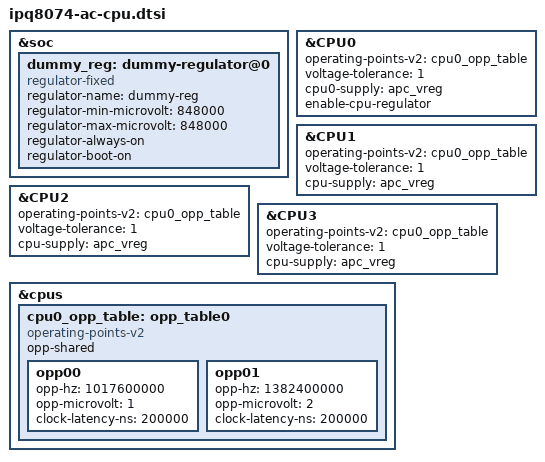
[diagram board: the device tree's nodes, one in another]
/*
 * Copyright (c) 2016-2018,2020 The Linux Foundation. All rights reserved.
 *
 * Permission to use, copy, modify, and/or distribute this software for any
 * purpose with or without fee is hereby granted, provided that the above
 * copyright notice and this permission notice appear in all copies.
 *
 * THE SOFTWARE IS PROVIDED "AS IS" AND THE AUTHOR DISCLAIMS ALL WARRANTIES
 * WITH REGARD TO THIS SOFTWARE INCLUDING ALL IMPLIED WARRANTIES OF
 * MERCHANTABILITY AND FITNESS. IN NO EVENT SHALL THE AUTHOR BE LIABLE FOR
 * ANY SPECIAL, DIRECT, INDIRECT, OR CONSEQUENTIAL DAMAGES OR ANY DAMAGES
 * WHATSOEVER RESULTING FROM LOSS OF USE, DATA OR PROFITS, WHETHER IN AN
 * ACTION OF CONTRACT, NEGLIGENCE OR OTHER TORTIOUS ACTION, ARISING OUT OF
 * OR IN CONNECTION WITH THE USE OR PERFORMANCE OF THIS SOFTWARE.
 */

&soc {
	dummy_reg: dummy-regulator@0 {
		compatible = "regulator-fixed";
		regulator-name = "dummy-reg";
		regulator-min-microvolt = <848000>;
		regulator-max-microvolt = <848000>;
		regulator-always-on;
		regulator-boot-on;
	};
};

&CPU0 {
	operating-points-v2 = <&cpu0_opp_table>;
	voltage-tolerance = <1>;
	cpu0-supply = <&apc_vreg>;
	enable-cpu-regulator;
};

&CPU1 {
	operating-points-v2 = <&cpu0_opp_table>;
	voltage-tolerance = <1>;
	cpu-supply = <&apc_vreg>;
};

&CPU2 {
	operating-points-v2 = <&cpu0_opp_table>;
	voltage-tolerance = <1>;
	cpu-supply = <&apc_vreg>;
};

&CPU3 {
	operating-points-v2 = <&cpu0_opp_table>;
	voltage-tolerance = <1>;
	cpu-supply = <&apc_vreg>;
};

&cpus {
	cpu0_opp_table: opp_table0 {
		compatible = "operating-points-v2";
		opp-shared;

		opp00 {
			opp-hz = /bits/ 64 <1017600000>;
			opp-microvolt = <1>;
			clock-latency-ns = <200000>;
		};
		opp01 {
			opp-hz = /bits/ 64 <1382400000>;
			opp-microvolt = <2>;
			clock-latency-ns = <200000>;
		};
	};
};
